# STM32F769xx register map
File version: 1.0
Registers are 32-bit, read-write, reset 0x0 unless marked. A register's access mark holds for its fields unless they carry their own. Offsets are from the block's base; [hi:lo] are bit positions; lines under a group give offsets from that group; {n}, {i} and the like mark numbered series.

## ADC
Base 0x40012300
Same registers: ADC123_COMMON 0x40012300 (alternate view of ADC)
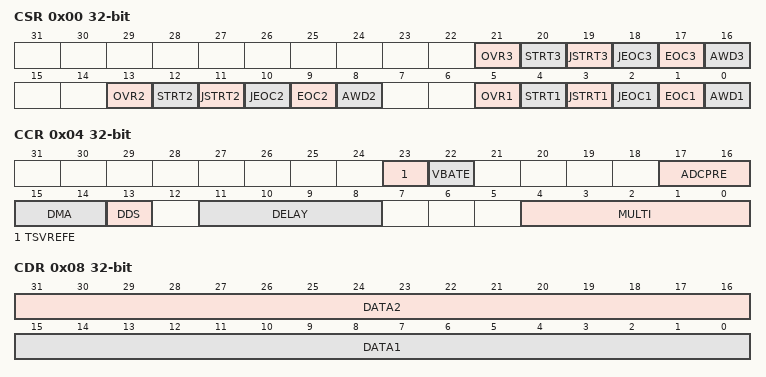
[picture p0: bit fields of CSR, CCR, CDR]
0x00 CSR — ADC Common status register
  [21] OVR3 — ADC3 Overrun flag
  [20] STRT3 — ADC3 Regular channel Start flag
  [19] JSTRT3 — ADC3 Injected channel Start flag
  [18] JEOC3 — ADC3 Injected channel end of conversion
  [17] EOC3 — ADC3 End of conversion
  [16] AWD3 — ADC3 Analog watchdog flag
  [13] OVR2 — ADC2 Overrun flag
  [12] STRT2 — ADC2 Regular channel Start flag
  [11] JSTRT2 — ADC2 Injected channel Start flag
  [10] JEOC2 — ADC2 Injected channel end of conversion
  [9] EOC2 — ADC2 End of conversion
  [8] AWD2 — ADC2 Analog watchdog flag
  [5] OVR1 — ADC1 Overrun flag
  [4] STRT1 — ADC1 Regular channel Start flag
  [3] JSTRT1 — ADC1 Injected channel Start flag
  [2] JEOC1 — ADC1 Injected channel end of conversion
  [1] EOC1 — ADC1 End of conversion
  [0] AWD1 — ADC1 Analog watchdog flag
0x04 CCR — ADC common control register
  [23] TSVREFE — Temperature Sensor and VREFINT Enable
  [22] VBATE — VBAT Enable
  [17:16] ADCPRE — ADCPRE[1:0] bits (ADC prescaler)
    0=DIV2 (ADC synchronous clock derived from AHB clock with prescaler division by 2); 1=DIV4 (ADC synchronous clock derived from AHB clock with prescaler division by 4); 2=DIV6 (ADC synchronous clock derived from AHB clock with prescaler division by 6); 3=DIV8 (ADC synchronous clock derived from AHB clock with prescaler division by 8)
  [15:14] DMA — DMA[1:0] bits (Direct Memory Access mode for multimode)
  [13] DDS — DMA disable selection (Multi-ADC mode)
  [11:8] DELAY — DELAY[3:0] bits (Delay between 2 sampling phases)
    {v}=DELAY_{v+5}CYCLES (ADC multimode delay between two sampling phases: {v+5} ADC clock cycles) (v=0..15)
  [4:0] MULTI — MULTI[4:0] bits (Multi-ADC mode selection)
    0=INDEPENDENT (ADC dual mode disabled (ADC independent mode)); 6=DUAL_REG_SIMULT (ADC dual mode enabled: group regular simultaneous); 7=DUAL_REG_INTERL (ADC dual mode enabled: Combined group regular interleaved); 5=DUAL_INJ_SIMULT (ADC dual mode enabled: group injected simultaneous); 9=DUAL_INJ_ALTERN (ADC dual mode enabled: group injected alternate trigger. Works only with external triggers (not internal SW start)); 1=DUAL_REG_SIM_INJ_SIM (ADC dual mode enabled: Combined group regular simultaneous + group injected simultaneous); 2=DUAL_REG_SIM_INJ_ALT (ADC dual mode enabled: Combined group regular simultaneous + group injected alternate trigger); 3=DUAL_REG_INT_INJ_SIM (ADC dual mode enabled: Combined group regular interleaved + group injected simultaneous); 17=TRIPLE_REG_SIM_INJ_SIM (ADC triple mode enabled: Combined group regular simultaneous + group injected simultaneous); 18=TRIPLE_REG_SIM_INJ_ALT (ADC triple mode enabled: Combined group regular simultaneous + group injected alternate trigger); 21=TRIPLE_INJ_SIMULT (ADC triple mode enabled: group injected simultaneous); 22=TRIPLE_REG_SIMULT (ADC triple mode enabled: group regular simultaneous); 23=TRIPLE_REG_INTERL (ADC triple mode enabled: Combined group regular interleaved)
0x08 CDR — ADC common regular data register for dual AND triple modes
  [31:16] DATA2 — 2nd data of a pair of regular conversions
  [15:0] DATA1 — 1st data of a pair of regular conversions

## SYSCFG — System configuration controller
Base 0x40013800
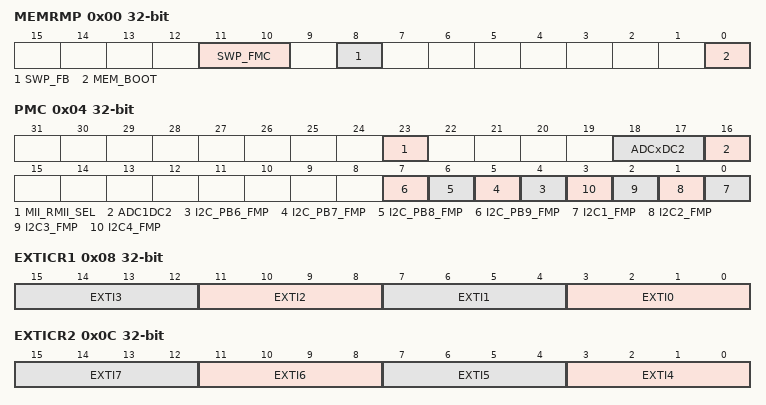
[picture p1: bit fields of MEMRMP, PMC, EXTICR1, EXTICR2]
0x00 MEMRMP — SYSCFG memory remap register
  [11:10] SWP_FMC — FMC Memory Mapping swapping
  [8] SWP_FB — User Flash Bank swap
    0=BANK1; 1=BANK2
  [0] MEM_BOOT — Boot information after Reset
    0=BOOT0 (Boot information after Reset); 1=BOOT1 (Boot information after Reset)
0x04 PMC — SYSCFG peripheral mode configuration register
  [23] MII_RMII_SEL — Ethernet PHY interface selection
    0=ETHMII (ETH Media MII interface); 1=ETHRMII (ETH Media RMII interface)
  [18:17] ADCxDC2 — Refer to AN4073 on how to use this bit
  [16] ADC1DC2 — Refer to AN4073 on how to use this bit
  [n-2] I2C_PB{n}_FMP (n=6..9) — PB{n}_FMP Fast Mode + Enable
  [n-1] I2C{n}_FMP (n=1..4) — I2C{n}_FMP I2C{n} Fast Mode + Enable
0x08 EXTICR1 — SYSCFG external interrupt configuration registers
  [4n+3:4n] EXTI{n} (n=0..3) — EXTI {n} configuration
0x0C EXTICR2 — SYSCFG external interrupt configuration registers
  [4n-13:4n-16] EXTI{n} (n=4..7) — EXTI {n} configuration
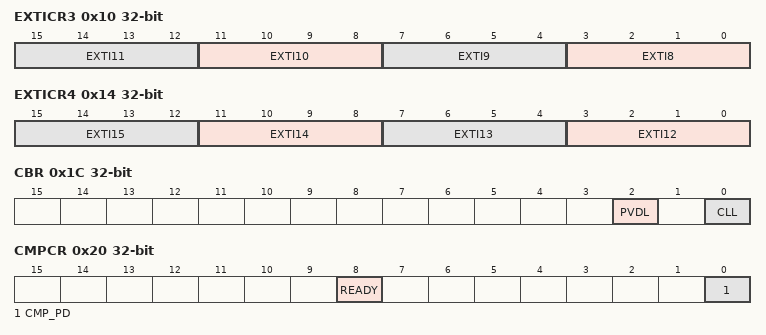
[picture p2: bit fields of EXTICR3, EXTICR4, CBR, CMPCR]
0x10 EXTICR3 — SYSCFG external interrupt configuration registers
  [4n-29:4n-32] EXTI{n} (n=8..11) — EXTI {n} configuration
0x14 EXTICR4 — SYSCFG external interrupt configuration registers
  [4n-45:4n-48] EXTI{n} (n=12..15) — EXTI {n} configuration
0x1C CBR — SYSCFG Class B register
  [2] PVDL — PVD Lock
  [0] CLL — Core Lockup Lock
0x20 CMPCR — SYSCFG Compensation cell control register
  [8] READY — Compensation cell ready flag
  [0] CMP_PD — Compensation cell power-down
